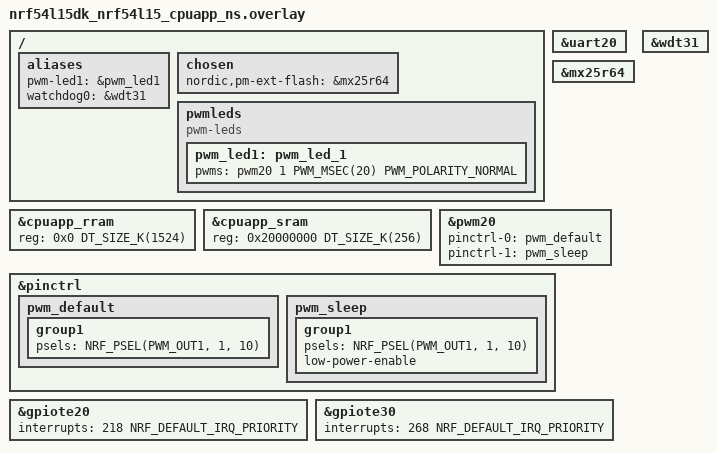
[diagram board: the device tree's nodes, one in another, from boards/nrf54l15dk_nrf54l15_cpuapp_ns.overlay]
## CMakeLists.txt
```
#
# Copyright (c) 2021 Nordic Semiconductor ASA
#
# SPDX-License-Identifier: LicenseRef-Nordic-5-Clause
#

cmake_minimum_required(VERSION 3.20.0)

find_package(Zephyr HINTS $ENV{ZEPHYR_BASE})

project(matter-light-bulb)

# Enable GNU STD support.
include(${ZEPHYR_CONNECTEDHOMEIP_MODULE_DIR}/config/nrfconnect/app/enable-gnu-std.cmake)

# NORDIC SDK APP START

# Include all source files that are located in the Matter common directory.
include(${ZEPHYR_NRF_MODULE_DIR}/samples/matter/common/cmake/source_common.cmake)

# Include Data Model utils
include(${ZEPHYR_NRF_MODULE_DIR}/samples/matter/common/cmake/data_model.cmake)

include(${ZEPHYR_NRF_MODULE_DIR}/samples/matter/common/cmake/zap_helpers.cmake)
ncs_get_zap_parent_dir(ZAP_PARENT_DIR)

target_include_directories(app PRIVATE
  src
  ${ZAP_PARENT_DIR}
)

if(CONFIG_AWS_IOT_INTEGRATION)
  add_subdirectory(src/aws_iot_integration)
endif()

target_sources(app PRIVATE
  src/app_task.cpp
  src/main.cpp
  src/zcl_callbacks.cpp
  ${CHIP_ROOT}/src/app/persistence/DeferredAttributePersistenceProvider.cpp
)

ncs_configure_data_model()
# NORDIC SDK APP END
```

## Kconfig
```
#
# Copyright (c) 2022 Nordic Semiconductor
#
# SPDX-License-Identifier: LicenseRef-Nordic-5-Clause
#
mainmenu "Matter nRF Connect Light Bulb Example Application"

# Sample configuration used for Thread networking
if OPENTHREAD

choice OPENTHREAD_NORDIC_LIBRARY_CONFIGURATION
	default OPENTHREAD_NORDIC_LIBRARY_FTD
endchoice

choice OPENTHREAD_DEVICE_TYPE
	default OPENTHREAD_FTD
endchoice

endif # OPENTHREAD

config CHIP_WIFI
	default y if BOARD_NRF7002DK_NRF5340_CPUAPP || SHIELD_NRF7002EB2
	select DEPRECATED if SOC_SERIES_NRF53X

source "$(ZEPHYR_CONNECTEDHOMEIP_MODULE_DIR)/config/nrfconnect/chip-module/Kconfig.features"
source "$(ZEPHYR_CONNECTEDHOMEIP_MODULE_DIR)/config/nrfconnect/chip-module/Kconfig.defaults"
source "$(ZEPHYR_NRF_MODULE_DIR)/samples/matter/common/src/Kconfig"
source "Kconfig.zephyr"
rsource "src/aws_iot_integration/Kconfig"
```

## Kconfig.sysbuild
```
#
# Copyright (c) 2023 Nordic Semiconductor ASA
#
# SPDX-License-Identifier: LicenseRef-Nordic-5-Clause
#

# This config has to be enabled manually for variants with shields, because sysbuild does not support it.
config WIFI_NRF70
	default y if BOARD_NRF7002DK

#### Radio core selection
config NRF_DEFAULT_IPC_RADIO
	default y

# Enable IEEE802.15.4 serialization to network core
# This config automatically pulls in the `overlay-802154.conf` in the ipc_radio image
config NETCORE_IPC_RADIO_IEEE802154
	default y if SOC_SERIES_NRF53X && !WIFI_NRF70

# Enable Bluetooth serialization to network core
# This config automatically pulls in the `overlay-bt_hci_ipc.conf` in the ipc_radio image
config NETCORE_IPC_RADIO_BT_HCI_IPC
	default y if SOC_SERIES_NRF53X

#### Bootloader
choice BOOTLOADER
	default BOOTLOADER_MCUBOOT if !BOARD_NRF21540DK
endchoice

if BOOTLOADER_MCUBOOT

#### DFU multi-image support
config DFU_MULTI_IMAGE_PACKAGE_BUILD
	default y

config DFU_MULTI_IMAGE_PACKAGE_APP
	default y

config PM_EXTERNAL_FLASH_MCUBOOT_SECONDARY
	default y

#### DFU network core configuration
if SOC_SERIES_NRF53X

choice MCUBOOT_MODE
	default MCUBOOT_MODE_OVERWRITE_ONLY
endchoice

choice BOOT_SIGNATURE_TYPE
	default BOOT_SIGNATURE_TYPE_RSA
endchoice

config SECURE_BOOT_NETCORE
	default y

config NETCORE_APP_UPDATE
	default y

config DFU_MULTI_IMAGE_PACKAGE_NET
	default y

if BOARD_NRF54L15DK || BOARD_NRF54LM20DK || BOARD_XIAO_NRF54LM20A

# Disable checking the external drivers for nRF54L15 and nRF54LM20 DKs.
config PM_OVERRIDE_EXTERNAL_DRIVER_CHECK
	default y

endif # BOARD_NRF54L15DK || BOARD_NRF54LM20DK || BOARD_XIAO_NRF54LM20A

endif # BOOTLOADER_MCUBOOT

# Store the Wi-Fi firmware patch on external flash by default for nRF5340 with nRF7002
if WIFI_NRF70 && SOC_NRF5340_CPUAPP

choice WIFI_PATCHES_EXT_FLASH_SUPPORT
	default WIFI_PATCHES_EXT_FLASH_STORE

endchoice

config DFU_MULTI_IMAGE_PACKAGE_WIFI_FW_PATCH
	default y

endif # WIFI_NRF70

endif # SOC_SERIES_NRF53X

#### Enable generating factory data
config MATTER_FACTORY_DATA_GENERATE
	default y if !BOARD_NRF21540DK && !BOARD_XIAO_NRF54LM20A

source "share/sysbuild/Kconfig"
```

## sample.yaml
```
sample:
  description: Matter Light Bulb example
  name: Matter Light Bulb
common:
  tags:
    - sysbuild
    - ci_samples_matter
tests:
  sample.matter.light_bulb.debug:
    sysbuild: true
    build_only: true
    integration_platforms:
      - nrf52840dk/nrf52840
      - nrf5340dk/nrf5340/cpuapp
      - nrf7002dk/nrf5340/cpuapp
      - nrf54l15dk/nrf54l15/cpuapp
      - nrf54l15dk/nrf54l15/cpuapp/ns
      - nrf54lm20dk/nrf54lm20a/cpuapp
    platform_allow:
      - nrf52840dk/nrf52840
      - nrf5340dk/nrf5340/cpuapp
      - nrf7002dk/nrf5340/cpuapp
      - nrf54l15dk/nrf54l15/cpuapp
      - nrf54l15dk/nrf54l15/cpuapp/ns
      - nrf54lm20dk/nrf54lm20a/cpuapp
  sample.matter.light_bulb.nrf7002eb2.debug:
    sysbuild: true
    build_only: true
    extra_args:
      - light_bulb_SHIELD=nrf7002eb2
      - SB_CONFIG_WIFI_NRF70=y
    integration_platforms:
      - nrf54lm20dk/nrf54lm20a/cpuapp
    platform_allow:
      - nrf54lm20dk/nrf54lm20a/cpuapp
  sample.matter.light_bulb.release:
    sysbuild: true
    build_only: true
    extra_args:
      - FILE_SUFFIX=release
      - SB_CONFIG_BOOTLOADER_MCUBOOT=y
      - SB_CONFIG_PARTITION_MANAGER=y
    integration_platforms:
      - nrf52840dk/nrf52840
      - nrf5340dk/nrf5340/cpuapp
      - nrf7002dk/nrf5340/cpuapp
      - nrf54l15dk/nrf54l15/cpuapp
      - nrf54lm20dk/nrf54lm20a/cpuapp
    platform_allow:
      - nrf52840dk/nrf52840
      - nrf5340dk/nrf5340/cpuapp
      - nrf7002dk/nrf5340/cpuapp
      - nrf54l15dk/nrf54l15/cpuapp
      - nrf54lm20dk/nrf54lm20a/cpuapp
  sample.matter.light_bulb.nrf7002eb2.release:
    sysbuild: true
    build_only: true
    extra_args:
      - FILE_SUFFIX=release
      - SB_CONFIG_BOOTLOADER_MCUBOOT=y
      - SB_CONFIG_PARTITION_MANAGER=y
      - light_bulb_SHIELD=nrf7002eb2
      - SB_CONFIG_WIFI_NRF70=y
    integration_platforms:
      - nrf54lm20dk/nrf54lm20a/cpuapp
    platform_allow:
      - nrf54lm20dk/nrf54lm20a/cpuapp
  sample.matter.light_bulb.ffs:
    sysbuild: true
    build_only: true
    extra_args:
      - CONFIG_CHIP_COMMISSIONABLE_DEVICE_TYPE=y
      - CONFIG_CHIP_ROTATING_DEVICE_ID=y
      - CONFIG_CHIP_DEVICE_TYPE=257
    integration_platforms:
      - nrf52840dk/nrf52840
      - nrf5340dk/nrf5340/cpuapp
      - nrf7002dk/nrf5340/cpuapp
      - nrf54l15dk/nrf54l15/cpuapp
      - nrf54lm20dk/nrf54lm20a/cpuapp
    platform_allow:
      - nrf52840dk/nrf52840
      - nrf5340dk/nrf5340/cpuapp
      - nrf7002dk/nrf5340/cpuapp
      - nrf54l15dk/nrf54l15/cpuapp
      - nrf54lm20dk/nrf54lm20a/cpuapp
  sample.matter.light_bulb.debug.nrf21540ek:
    sysbuild: true
    build_only: true
    extra_args:
      - light_bulb_SHIELD=nrf21540ek
    integration_platforms:
      - nrf52840dk/nrf52840
    platform_allow: nrf52840dk/nrf52840
  sample.matter.light_bulb.debug.nrf21540ek_fwd:
    sysbuild: true
    build_only: true
    extra_args:
      - light_bulb_SHIELD=nrf21540ek
      - ipc_radio_SHIELD=nrf21540ek
    integration_platforms:
      - nrf5340dk/nrf5340/cpuapp
    platform_allow: nrf5340dk/nrf5340/cpuapp
  # Sample to execute load tests
  sample.matter.light_bulb.memory_profiling:
    sysbuild: true
    build_only: true
    extra_args:
      - CONFIG_CHIP_MEMORY_PROFILING=y
      - CONFIG_SHELL_MINIMAL=y
      - CONFIG_CHIP_FACTORY_RESET_TIME_MEASUREMENT=y
    platform_allow:
      - nrf52840dk/nrf52840
      - nrf5340dk/nrf5340/cpuapp
      - nrf54l15dk/nrf54l15/cpuapp
      - nrf7002dk/nrf5340/cpuapp
      - nrf54lm20dk/nrf54lm20a/cpuapp
    integration_platforms:
      - nrf52840dk/nrf52840
      - nrf5340dk/nrf5340/cpuapp
      - nrf54l15dk/nrf54l15/cpuapp
      - nrf7002dk/nrf5340/cpuapp
      - nrf54lm20dk/nrf54lm20a/cpuapp
  sample.matter.light_bulb.nrf7002eb2.memory_profiling:
    sysbuild: true
    build_only: true
    extra_args:
      - CONFIG_CHIP_MEMORY_PROFILING=y
      - CONFIG_SHELL_MINIMAL=y
      - CONFIG_CHIP_FACTORY_RESET_TIME_MEASUREMENT=y
      - light_bulb_SHIELD=nrf7002eb2
      - SB_CONFIG_WIFI_NRF70=y
    platform_allow:
      - nrf54lm20dk/nrf54lm20a/cpuapp
    integration_platforms:
      - nrf54lm20dk/nrf54lm20a/cpuapp
  sample.matter.light_bulb.aws:
    sysbuild: true
    build_only: true
    extra_args:
      - EXTRA_CONF_FILE="overlay-aws-iot-integration.conf"
    platform_allow: nrf7002dk/nrf5340/cpuapp
    integration_platforms:
      - nrf7002dk/nrf5340/cpuapp
```

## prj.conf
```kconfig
#
# Copyright (c) 2022 Nordic Semiconductor ASA
#
# SPDX-License-Identifier: LicenseRef-Nordic-5-Clause
#

# Enable CHIP
CONFIG_CHIP=y
CONFIG_CHIP_PROJECT_CONFIG="src/chip_project_config.h"
CONFIG_CHIP_DEVICE_PRODUCT_NAME="Matter Light Bulb"

# Configure ZAP file name
CONFIG_NCS_SAMPLE_MATTER_ZAP_FILE_PATH="${APPLICATION_CONFIG_DIR}/src/default_zap/light_bulb.zap"

# 32773 == 0x8005 (example lighting-app)
CONFIG_CHIP_DEVICE_PRODUCT_ID=32773
CONFIG_STD_CPP17=y

# Enable Matter pairing automatically on application start.
CONFIG_CHIP_ENABLE_PAIRING_AUTOSTART=y

# Enable Matter extended announcement and increase duration to 1 hour.
CONFIG_CHIP_BLE_EXT_ADVERTISING=y
CONFIG_CHIP_BLE_ADVERTISING_DURATION=60

# Add support for LEDs and buttons on Nordic development kits
CONFIG_DK_LIBRARY=y
CONFIG_PWM=y

# Bluetooth Low Energy configuration
CONFIG_BT_DEVICE_NAME="MatterLight"

# Other settings
CONFIG_THREAD_NAME=y
CONFIG_MPU_STACK_GUARD=y
CONFIG_RESET_ON_FATAL_ERROR=n
CONFIG_CHIP_LIB_SHELL=y
CONFIG_NCS_SAMPLE_MATTER_TEST_SHELL=y

# Reduce application size
CONFIG_USE_SEGGER_RTT=n

# Enable Factory Data feature
CONFIG_CHIP_FACTORY_DATA=y
CONFIG_CHIP_FACTORY_DATA_BUILD=y
```

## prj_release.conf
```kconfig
#
# Copyright (c) 2022 Nordic Semiconductor ASA
#
# SPDX-License-Identifier: LicenseRef-Nordic-5-Clause
#

# Enable CHIP
CONFIG_CHIP=y
CONFIG_CHIP_PROJECT_CONFIG="src/chip_project_config.h"
CONFIG_CHIP_DEVICE_PRODUCT_NAME="Matter Light Bulb"

# Configure ZAP file name
CONFIG_NCS_SAMPLE_MATTER_ZAP_FILE_PATH="${APPLICATION_CONFIG_DIR}/src/default_zap/light_bulb.zap"

# 32773 == 0x8005 (example lighting-app)
CONFIG_CHIP_DEVICE_PRODUCT_ID=32773
CONFIG_STD_CPP17=y

# Enable Matter pairing automatically on application start.
CONFIG_CHIP_ENABLE_PAIRING_AUTOSTART=y

# Enable Matter extended announcement and increase duration to 1 hour.
CONFIG_CHIP_BLE_EXT_ADVERTISING=y
CONFIG_CHIP_BLE_ADVERTISING_DURATION=60

# Add support for LEDs and buttons on Nordic development kits
CONFIG_DK_LIBRARY=y
CONFIG_PWM=y

# Bluetooth Low Energy configuration
CONFIG_BT_DEVICE_NAME="MatterLight"

# Enable system reset on fatal error
CONFIG_RESET_ON_FATAL_ERROR=y

# Disable all debug features
CONFIG_USE_SEGGER_RTT=n
CONFIG_SHELL=n
CONFIG_OPENTHREAD_SHELL=n
CONFIG_CONSOLE=n
CONFIG_UART_CONSOLE=n
CONFIG_SERIAL=n
CONFIG_LOG=n
CONFIG_LOG_MODE_MINIMAL=n
CONFIG_ASSERT_VERBOSE=n
CONFIG_ASSERT_NO_FILE_INFO=y
CONFIG_PRINTK=n
CONFIG_PRINTK_SYNC=n
CONFIG_THREAD_NAME=n
CONFIG_BOOT_BANNER=n

# Enable Factory Data feature
CONFIG_CHIP_FACTORY_DATA=y
CONFIG_CHIP_FACTORY_DATA_BUILD=y

# Enable Watchdog
CONFIG_NCS_SAMPLE_MATTER_WATCHDOG=y

# Enable LTO to decrease the flash usage.
CONFIG_LTO=y
CONFIG_ISR_TABLES_LOCAL_DECLARATION=y
```

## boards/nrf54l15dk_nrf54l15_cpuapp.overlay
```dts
/*
 * Copyright (c) 2024 Nordic Semiconductor ASA
 *
 * SPDX-License-Identifier: LicenseRef-Nordic-5-Clause
 */


/ {
	chosen {
		nordic,pm-ext-flash = &mx25r64;
	};

	aliases {
		/* Configure PWM module for led1 (LED2 on the board) */
		pwm-led1 = &pwm_led1;

		/* Use watchdog wdt31 as the application watchdog */
		watchdog0 = &wdt31;
	};

	pwmleds {
		compatible = "pwm-leds";
		pwm_led1: pwm_led_1 {
			pwms = <&pwm20 1 PWM_MSEC(20) PWM_POLARITY_NORMAL>;
		};
	};
};

/* restore full RRAM and SRAM space - by default some parts are dedicated to FLRP */
&cpuapp_rram {
	reg = <0x0 DT_SIZE_K(1524)>;
};

&cpuapp_sram {
	reg = <0x20000000 DT_SIZE_K(256)>;
	ranges = <0x0 0x20000000 0x40000>;
};

/* TODO: re-enable HWFC once it's fixed */
&uart20 {
	/delete-property/ hw-flow-control;
};

&mx25r64 {
	status = "okay";
};

&pwm20 {
	status = "okay";
	pinctrl-0 = <&pwm_default>;
	pinctrl-1 = <&pwm_sleep>;
	pinctrl-names = "default", "sleep";
};

&pinctrl {
	pwm_default: pwm_default {
		group1 {
			psels = <NRF_PSEL(PWM_OUT1, 1, 10)>;
		};
	};
	pwm_sleep: pwm_sleep {
		group1 {
			psels = <NRF_PSEL(PWM_OUT1, 1, 10)>;
			low-power-enable;
		};
	};
};

&wdt31 {
	status = "okay";
};
```

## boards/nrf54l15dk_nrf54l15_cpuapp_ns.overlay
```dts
/*
 * Copyright (c) 2024 Nordic Semiconductor ASA
 *
 * SPDX-License-Identifier: LicenseRef-Nordic-5-Clause
 */

/ {
	aliases {
		/* Configure PWM module for led1 (LED2 on the board) */
		pwm-led1 = &pwm_led1;

		/* Use watchdog wdt31 as the application watchdog */
		watchdog0 = &wdt31;
	};

	chosen {
		nordic,pm-ext-flash = &mx25r64;
	};

	pwmleds {
		compatible = "pwm-leds";
		pwm_led1: pwm_led_1 {
			pwms = <&pwm20 1 PWM_MSEC(20) PWM_POLARITY_NORMAL>;
		};
	};
};

/* restore full RRAM and SRAM space - by default some parts are dedicated to FLRP */
&cpuapp_rram {
	reg = <0x0 DT_SIZE_K(1524)>;
};

&cpuapp_sram {
	reg = <0x20000000 DT_SIZE_K(256)>;
	ranges = <0x0 0x20000000 0x40000>;
};

/* TODO: re-enable HWFC once it's fixed */
&uart20 {
	/delete-property/ hw-flow-control;
};

&mx25r64 {
	status = "okay";
};

&pwm20 {
	status = "okay";
	pinctrl-0 = <&pwm_default>;
	pinctrl-1 = <&pwm_sleep>;
	pinctrl-names = "default", "sleep";
};

&pinctrl {
	pwm_default: pwm_default {
		group1 {
			psels = <NRF_PSEL(PWM_OUT1, 1, 10)>;
		};
	};
	pwm_sleep: pwm_sleep {
		group1 {
			psels = <NRF_PSEL(PWM_OUT1, 1, 10)>;
			low-power-enable;
		};
	};
};

&wdt31 {
	status = "okay";
};

/* Change IRQ ids to handle button interrupts.
 * The default values for nRF54L15 are 219 and 269,
 * but with TF-M they are reserved for the secure domain
 * (218 and 268 are reserved for the non-secure domain).
 */
&gpiote20 {
	interrupts = <218 NRF_DEFAULT_IRQ_PRIORITY>;
};

&gpiote30 {
	interrupts = <268 NRF_DEFAULT_IRQ_PRIORITY>;
};
```

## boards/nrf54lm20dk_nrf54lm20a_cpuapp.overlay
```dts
/*
 * Copyright (c) 2025 Nordic Semiconductor ASA
 *
 * SPDX-License-Identifier: LicenseRef-Nordic-5-Clause
 */

/ {
	chosen {
		nordic,pm-ext-flash = &mx25r64;
	};

	aliases {
		/* Configure PWM module for led1 (LED2 on the board) */
		pwm-led1 = &pwm_led1;

		/* Use watchdog wdt31 as the application watchdog */
		watchdog0 = &wdt31;
	};

	pwmleds {
		compatible = "pwm-leds";
		pwm_led1: pwm_led_1 {
			pwms = <&pwm20 1 PWM_MSEC(20) PWM_POLARITY_NORMAL>;
		};
	};
};

&pwm20 {
	status = "okay";
	pinctrl-0 = <&pwm_default>;
	pinctrl-1 = <&pwm_sleep>;
	pinctrl-names = "default", "sleep";
};

&pinctrl {
	pwm_default: pwm_default {
		group1 {
			psels = <NRF_PSEL(PWM_OUT1, 1, 25)>;
		};
	};
	pwm_sleep: pwm_sleep {
		group1 {
			psels = <NRF_PSEL(PWM_OUT1, 1, 25)>;
			low-power-enable;
		};
	};
};

&mx25r64 {
	status = "okay";
};

&wdt31 {
	status = "okay";
};
```

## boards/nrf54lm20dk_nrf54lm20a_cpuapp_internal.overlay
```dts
/*
 * Copyright (c) 2025 Nordic Semiconductor ASA
 *
 * SPDX-License-Identifier: LicenseRef-Nordic-5-Clause
 */

/ {
	aliases {
		/* Configure PWM module for led1 (LED2 on the board) */
		pwm-led1 = &pwm_led1;

		/* Use watchdog wdt31 as the application watchdog */
		watchdog0 = &wdt31;
	};

	pwmleds {
		compatible = "pwm-leds";
		pwm_led1: pwm_led_1 {
			pwms = <&pwm20 1 PWM_MSEC(20) PWM_POLARITY_NORMAL>;
		};
	};
};

&pwm20 {
	status = "okay";
	pinctrl-0 = <&pwm_default>;
	pinctrl-1 = <&pwm_sleep>;
	pinctrl-names = "default", "sleep";
};

&pinctrl {
	pwm_default: pwm_default {
		group1 {
			psels = <NRF_PSEL(PWM_OUT1, 1, 25)>;
		};
	};
	pwm_sleep: pwm_sleep {
		group1 {
			psels = <NRF_PSEL(PWM_OUT1, 1, 25)>;
			low-power-enable;
		};
	};
};

&mx25r64 {
	status = "disabled";
};

&wdt31 {
	status = "okay";
};
```

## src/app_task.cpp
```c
/*
 * Copyright (c) 2021 Nordic Semiconductor ASA
 *
 * SPDX-License-Identifier: LicenseRef-Nordic-5-Clause
 */

#include "app_task.h"

#ifdef CONFIG_AWS_IOT_INTEGRATION
#include "aws_iot_integration.h"
#endif

#include "app/matter_init.h"
#include "app/task_executor.h"

#if defined(CONFIG_PWM)
#include "pwm/pwm_device.h"
#endif

#include "clusters/identify.h"

#include <app-common/zap-generated/attributes/Accessors.h>
#include <app/persistence/AttributePersistenceProviderInstance.h>
#include <app/persistence/DefaultAttributePersistenceProvider.h>
#include <app/persistence/DeferredAttributePersistenceProvider.h>
#include <app/server/Server.h>
#include <setup_payload/OnboardingCodesUtil.h>

#include <zephyr/logging/log.h>

LOG_MODULE_DECLARE(app, CONFIG_CHIP_APP_LOG_LEVEL);

using namespace ::chip;
using namespace ::chip::app;
using namespace ::chip::DeviceLayer;

namespace
{
constexpr EndpointId kLightEndpointId = 1;
constexpr uint8_t kDefaultMinLevel = 0;
constexpr uint8_t kDefaultMaxLevel = 254;

Nrf::Matter::IdentifyCluster sIdentifyCluster(kLightEndpointId, true, []() {
	Nrf::PostTask([] { Nrf::GetBoard().GetLED(Nrf::DeviceLeds::LED2).Set(false); });
#if defined(CONFIG_PWM)
	Nrf::PostTask([] { AppTask::Instance().GetPWMDevice().ApplyLevel(); });
#endif
});

#if defined(CONFIG_PWM)
const struct pwm_dt_spec sLightPwmDevice = PWM_DT_SPEC_GET(DT_ALIAS(pwm_led1));
#endif

/* Define a custom attribute persister which makes actual write of the CurrentLevel attribute value
 * to the non-volatile storage only when it has remained constant for 5 seconds. This is to reduce
 * the flash wearout when the attribute changes frequently as a result of MoveToLevel command.
 * DeferredAttribute object describes a deferred attribute, but also holds a buffer with a value to
 * be written, so it must live so long as the DeferredAttributePersistenceProvider object.
 */
DeferredAttribute gCurrentLevelPersister(ConcreteAttributePath(kLightEndpointId, Clusters::LevelControl::Id,
							       Clusters::LevelControl::Attributes::CurrentLevel::Id));

/* Deferred persistence will be auto-initialized as soon as the default persistence is initialized */
DefaultAttributePersistenceProvider gSimpleAttributePersistence;
DeferredAttributePersistenceProvider gDeferredAttributePersister(gSimpleAttributePersistence,
								 Span<DeferredAttribute>(&gCurrentLevelPersister, 1),
								 System::Clock::Milliseconds32(5000));

#define APPLICATION_BUTTON_MASK DK_BTN2_MSK
} /* namespace */

void AppTask::LightingActionEventHandler(const LightingEvent &event)
{
#if defined(CONFIG_PWM)
	Nrf::PWMDevice::Action_t action = Nrf::PWMDevice::INVALID_ACTION;
	int32_t actor = 0;
	if (event.Actor == LightingActor::Button) {
		action = Instance().mPWMDevice.IsTurnedOn() ? Nrf::PWMDevice::OFF_ACTION : Nrf::PWMDevice::ON_ACTION;
		actor = static_cast<int32_t>(event.Actor);
	}

	if (action == Nrf::PWMDevice::INVALID_ACTION || !Instance().mPWMDevice.InitiateAction(action, actor, NULL)) {
		LOG_INF("An action could not be initiated.");
	}
#else
	Nrf::GetBoard().GetLED(Nrf::DeviceLeds::LED2).Set(!Nrf::GetBoard().GetLED(Nrf::DeviceLeds::LED2).GetState());
#endif
}

void AppTask::ButtonEventHandler(Nrf::ButtonState state, Nrf::ButtonMask hasChanged)
{
	if ((APPLICATION_BUTTON_MASK & hasChanged) & state) {
		Nrf::PostTask([] {
			LightingEvent event;
			event.Actor = LightingActor::Button;
			LightingActionEventHandler(event);
		});
	}
}

#ifdef CONFIG_AWS_IOT_INTEGRATION
bool AppTask::AWSIntegrationCallback(struct aws_iot_integration_cb_data *data)
{
	LOG_INF("Attribute change requested from AWS IoT: %d", data->value);

	Protocols::InteractionModel::Status status;

	VerifyOrDie(data->error == 0);

	if (data->attribute_id == ATTRIBUTE_ID_ONOFF) {
		/* write the new on/off value */
		status = Clusters::OnOff::Attributes::OnOff::Set(kLightEndpointId, data->value);
		if (status != Protocols::InteractionModel::Status::Success) {
			LOG_ERR("Updating on/off cluster failed: %x", to_underlying(status));
			return false;
		}
	} else if (data->attribute_id == ATTRIBUTE_ID_LEVEL_CONTROL) {
		/* write the current level */
		status = Clusters::LevelControl::Attributes::CurrentLevel::Set(kLightEndpointId, data->value);

		if (status != Protocols::InteractionModel::Status::Success) {
			LOG_ERR("Updating level cluster failed: %x", to_underlying(status));
			return false;
		}
	}

	return true;
}
#endif /* CONFIG_AWS_IOT_INTEGRATION */

#if defined(CONFIG_PWM)
void AppTask::ActionInitiated(Nrf::PWMDevice::Action_t action, int32_t actor)
{
	if (action == Nrf::PWMDevice::ON_ACTION) {
		LOG_INF("Turn On Action has been initiated");
	} else if (action == Nrf::PWMDevice::OFF_ACTION) {
		LOG_INF("Turn Off Action has been initiated");
	} else if (action == Nrf::PWMDevice::LEVEL_ACTION) {
		LOG_INF("Level Action has been initiated");
	}
}

void AppTask::ActionCompleted(Nrf::PWMDevice::Action_t action, int32_t actor)
{
	if (action == Nrf::PWMDevice::ON_ACTION) {
		LOG_INF("Turn On Action has been completed");
	} else if (action == Nrf::PWMDevice::OFF_ACTION) {
		LOG_INF("Turn Off Action has been completed");
	} else if (action == Nrf::PWMDevice::LEVEL_ACTION) {
		LOG_INF("Level Action has been completed");
	}

	if (actor == static_cast<int32_t>(LightingActor::Button)) {
		Instance().UpdateClusterState();
	}
}
#endif /* CONFIG_PWM */

void AppTask::UpdateClusterState()
{
	SystemLayer().ScheduleLambda([this] {
#if defined(CONFIG_PWM)
		/* write the new on/off value */
		Protocols::InteractionModel::Status status =
			Clusters::OnOff::Attributes::OnOff::Set(kLightEndpointId, mPWMDevice.IsTurnedOn());
#else
		Protocols::InteractionModel::Status status = Clusters::OnOff::Attributes::OnOff::Set(
			kLightEndpointId, Nrf::GetBoard().GetLED(Nrf::DeviceLeds::LED2).GetState());
#endif
		if (status != Protocols::InteractionModel::Status::Success) {
			LOG_ERR("Updating on/off cluster failed: %x", to_underlying(status));
		}

#if defined(CONFIG_PWM)
		/* write the current level */
		status = Clusters::LevelControl::Attributes::CurrentLevel::Set(kLightEndpointId, mPWMDevice.GetLevel());
#else
		/* write the current level */
		if (Nrf::GetBoard().GetLED(Nrf::DeviceLeds::LED2).GetState()) {
			status = Clusters::LevelControl::Attributes::CurrentLevel::Set(kLightEndpointId, 100);
		} else {
			status = Clusters::LevelControl::Attributes::CurrentLevel::Set(kLightEndpointId, 0);
		}
#endif

		if (status != Protocols::InteractionModel::Status::Success) {
			LOG_ERR("Updating level cluster failed: %x", to_underlying(status));
		}
	});
}

void AppTask::InitPWMDDevice()
{
#if defined(CONFIG_PWM)
	/* Initialize lighting device (PWM) */
	uint8_t minLightLevel = kDefaultMinLevel;
	Clusters::LevelControl::Attributes::MinLevel::Get(kLightEndpointId, &minLightLevel);

	uint8_t maxLightLevel = kDefaultMaxLevel;
	Clusters::LevelControl::Attributes::MaxLevel::Get(kLightEndpointId, &maxLightLevel);

	Clusters::LevelControl::Attributes::CurrentLevel::TypeInfo::Type currentLevel;
	Clusters::LevelControl::Attributes::CurrentLevel::Get(kLightEndpointId, currentLevel);

	int ret =
		mPWMDevice.Init(&sLightPwmDevice, minLightLevel, maxLightLevel, currentLevel.ValueOr(kDefaultMaxLevel));
	if (ret != 0) {
		LOG_ERR("Failed to initialize PWD device.");
	}

	mPWMDevice.SetCallbacks(ActionInitiated, ActionCompleted);
#endif
}

CHIP_ERROR AppTask::Init()
{
	/* Initialize Matter stack */
	ReturnErrorOnFailure(Nrf::Matter::PrepareServer(Nrf::Matter::InitData{ .mPostServerInitClbk = []() {
		app::SetAttributePersistenceProvider(&gDeferredAttributePersister);
		gSimpleAttributePersistence.Init(Nrf::Matter::GetPersistentStorageDelegate());
		return CHIP_NO_ERROR;
	} }));

	if (!Nrf::GetBoard().Init(ButtonEventHandler)) {
		LOG_ERR("User interface initialization failed.");
		return CHIP_ERROR_INCORRECT_STATE;
	}

	/* Register Matter event handler that controls the connectivity status LED based on the captured Matter network
	 * state. */
	ReturnErrorOnFailure(Nrf::Matter::RegisterEventHandler(Nrf::Board::DefaultMatterEventHandler, 0));

#ifdef CONFIG_AWS_IOT_INTEGRATION
	int retAws = aws_iot_integration_register_callback(AWSIntegrationCallback);
	if (retAws) {
		LOG_ERR("aws_iot_integration_register_callback() failed");
		return chip::System::MapErrorZephyr(retAws);
	}
#endif

	ReturnErrorOnFailure(sIdentifyCluster.Init());

	return Nrf::Matter::StartServer();
}

CHIP_ERROR AppTask::StartApp()
{
	ReturnErrorOnFailure(Init());

	while (true) {
		Nrf::DispatchNextTask();
	}

	return CHIP_NO_ERROR;
}
```

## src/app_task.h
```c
/*
 * Copyright (c) 2021 Nordic Semiconductor ASA
 *
 * SPDX-License-Identifier: LicenseRef-Nordic-5-Clause
 */

#pragma once

#include "board/board.h"
#include "pwm/pwm_device.h"

#include <platform/CHIPDeviceLayer.h>

struct k_timer;
struct Identify;

enum class LightingActor : uint8_t { Remote, Button };

struct LightingEvent {
	uint8_t Action;
	LightingActor Actor;
};

class AppTask {
public:
	static AppTask &Instance()
	{
		static AppTask sAppTask;
		return sAppTask;
	};

	CHIP_ERROR StartApp();

	void UpdateClusterState();
	void InitPWMDDevice();
	Nrf::PWMDevice &GetPWMDevice() { return mPWMDevice; }

private:
	CHIP_ERROR Init();

	static void LightingActionEventHandler(const LightingEvent &event);
	static void ButtonEventHandler(Nrf::ButtonState state, Nrf::ButtonMask hasChanged);

	static void ActionInitiated(Nrf::PWMDevice::Action_t action, int32_t actor);
	static void ActionCompleted(Nrf::PWMDevice::Action_t action, int32_t actor);

#ifdef CONFIG_AWS_IOT_INTEGRATION
	static bool AWSIntegrationCallback(struct aws_iot_integration_cb_data *data);
#endif

	Nrf::PWMDevice mPWMDevice;
};
```

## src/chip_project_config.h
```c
/*
 * Copyright (c) 2021 Nordic Semiconductor ASA
 *
 * SPDX-License-Identifier: LicenseRef-Nordic-5-Clause
 */

/**
 *    @file
 *          Example project configuration file for CHIP.
 *
 *          This is a place to put application or project-specific overrides
 *          to the default configuration values for general CHIP features.
 *
 */

#pragma once

/* Reduce some flash space when the CONFIG_CHIP_MEMORY_PROFILING is selected */
#ifdef CONFIG_CHIP_MEMORY_PROFILING
#define CHIP_CONFIG_LOG_MODULE_SecureChannel_PROGRESS 0
#define CHIP_CONFIG_LOG_MODULE_FabricProvisioning_PROGRESS 0
#define CHIP_CONFIG_LOG_MODULE_InteractionModel_PROGRESS 0
#define CHIP_CONFIG_LOG_MODULE_InteractionModel_DETAIL 0
#define CHIP_CONFIG_LOG_MODULE_DataManagement_PROGRESS 0
#endif
```

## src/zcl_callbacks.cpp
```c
/*
 * Copyright (c) 2021 Nordic Semiconductor ASA
 *
 * SPDX-License-Identifier: LicenseRef-Nordic-5-Clause
 */

#include <lib/support/logging/CHIPLogging.h>

#include "app_task.h"

#ifdef CONFIG_AWS_IOT_INTEGRATION
#include "aws_iot_integration.h"
#endif

#include <app-common/zap-generated/attributes/Accessors.h>
#include <app-common/zap-generated/ids/Attributes.h>
#include <app-common/zap-generated/ids/Clusters.h>
#include <app/ConcreteAttributePath.h>

using namespace ::chip;
using namespace ::chip::app::Clusters;
using namespace ::chip::app::Clusters::OnOff;

void MatterPostAttributeChangeCallback(const chip::app::ConcreteAttributePath &attributePath, uint8_t type,
				       uint16_t size, uint8_t *value)
{
	ClusterId clusterId = attributePath.mClusterId;
	AttributeId attributeId = attributePath.mAttributeId;

	if (clusterId == OnOff::Id && attributeId == OnOff::Attributes::OnOff::Id) {
		ChipLogProgress(Zcl, "Cluster OnOff: attribute OnOff set to %" PRIu8 "", *value);

#if defined(CONFIG_PWM)
		AppTask::Instance().GetPWMDevice().InitiateAction(*value ? Nrf::PWMDevice::ON_ACTION :
									   Nrf::PWMDevice::OFF_ACTION,
								  static_cast<int32_t>(LightingActor::Remote), value);
#else
		Nrf::GetBoard().GetLED(Nrf::DeviceLeds::LED2).Set(*value);
#endif

#ifdef CONFIG_AWS_IOT_INTEGRATION
		aws_iot_integration_attribute_set(ATTRIBUTE_ID_ONOFF, *value);
#endif

	} else if (clusterId == LevelControl::Id && attributeId == LevelControl::Attributes::CurrentLevel::Id) {
		ChipLogProgress(Zcl, "Cluster LevelControl: attribute CurrentLevel set to %" PRIu8 "", *value);
#if defined(CONFIG_PWM)
		if (AppTask::Instance().GetPWMDevice().IsTurnedOn()) {
			AppTask::Instance().GetPWMDevice().InitiateAction(
				Nrf::PWMDevice::LEVEL_ACTION, static_cast<int32_t>(LightingActor::Remote), value);
		} else {
			ChipLogDetail(Zcl, "LED is off. Try to use move-to-level-with-on-off instead of move-to-level");
		}
#endif

#ifdef CONFIG_AWS_IOT_INTEGRATION
		aws_iot_integration_attribute_set(ATTRIBUTE_ID_LEVEL_CONTROL, *value);
#endif
	}
}

/** @brief OnOff Cluster Init
 *
 * This function is called when a specific cluster is initialized. It gives the
 * application an opportunity to take care of cluster initialization procedures.
 * It is called exactly once for each endpoint where cluster is present.
 *
 * @param endpoint   Ver.: always
 *
 * TODO Issue #3841
 * emberAfOnOffClusterInitCallback happens before the stack initialize the cluster
 * attributes to the default value.
 * The logic here expects something similar to the deprecated Plugins callback
 * emberAfPluginOnOffClusterServerPostInitCallback.
 *
 */
void emberAfOnOffClusterInitCallback(EndpointId endpoint)
{
	Protocols::InteractionModel::Status status;
	bool storedValue;

	/* Read storedValue on/off value */
	status = Attributes::OnOff::Get(endpoint, &storedValue);

	if (status == Protocols::InteractionModel::Status::Success) {
		/* Set actual state to the cluster state that was last persisted */
#if defined(CONFIG_PWM)
		AppTask::Instance().InitPWMDDevice();

		AppTask::Instance().GetPWMDevice().InitiateAction(
			storedValue ? Nrf::PWMDevice::ON_ACTION : Nrf::PWMDevice::OFF_ACTION,
			static_cast<int32_t>(LightingActor::Remote), reinterpret_cast<uint8_t *>(&storedValue));
#else
		Nrf::GetBoard().GetLED(Nrf::DeviceLeds::LED2).Set(storedValue);
#endif
	}

	AppTask::Instance().UpdateClusterState();
}
```
